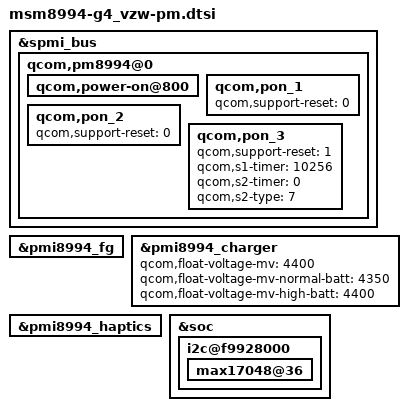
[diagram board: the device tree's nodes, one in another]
/* Copyright (c) 2014, The Linux Foundation. All rights reserved.
 *
 * This program is free software; you can redistribute it and/or modify
 * it under the terms of the GNU General Public License version 2 and
 * only version 2 as published by the Free Software Foundation.
 *
 * This program is distributed in the hope that it will be useful,
 * but WITHOUT ANY WARRANTY; without even the implied warranty of
 * MERCHANTABILITY or FITNESS FOR A PARTICULAR PURPOSE.  See the
 * GNU General Public License for more details.
 */

#include "../msm8994-g4_common/msm8994-common-pm.dtsi"

&spmi_bus {
	qcom,pm8994@0 {
		qcom,power-on@800 {
			status = "ok";
		};

		qcom,pon_1 { /* KPD_PWR_N reset */
			status = "ok";
			qcom,support-reset = <0>;
		};

		qcom,pon_2 { /* RESIN_N reset   */
			status = "ok";
			qcom,support-reset = <0>;
		};

		qcom,pon_3 { /* KPD_PWR_N AND RESIN_N reset */
			status = "ok";
			qcom,support-reset = <1>;
			qcom,s1-timer = <10256>;
			qcom,s2-timer = <0>;
			qcom,s2-type = <7>;
		};
	};
};

&pmi8994_fg {
	status = "ok";
};

&pmi8994_charger {
	status = "ok";

	qcom,float-voltage-mv = <4400>;
	qcom,float-voltage-mv-normal-batt = <4350>;
	qcom,float-voltage-mv-high-batt = <4400>;
};

&pmi8994_haptics {
	status = "ok";
};

&soc {
	i2c@f9928000 { /* BLSP1 QUP6 */
		max17048@36 {
			status = "ok";
		};
	};
};

